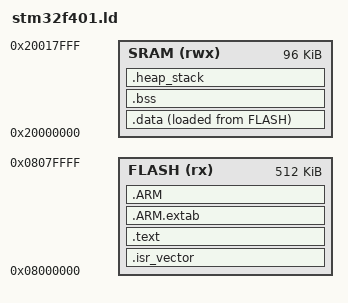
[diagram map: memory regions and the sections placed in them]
/*
 * Linker script for STM32F401RE.
 * Flash: 512 KB at 0x08000000
 * SRAM:  96 KB at 0x20000000
 *
 * Reference: STM32F401xB/C/D/E data sheet DS9716 Rev 7.
 */

MEMORY
{
    FLASH  (rx)  : ORIGIN = 0x08000000, LENGTH = 512K
    SRAM   (rwx) : ORIGIN = 0x20000000, LENGTH = 96K
}

ENTRY(Reset_Handler)

SECTIONS
{
    .isr_vector :
    {
        . = ALIGN(4);
        KEEP(*(.isr_vector))
        . = ALIGN(4);
    } > FLASH

    .text :
    {
        . = ALIGN(4);
        *(.text)
        *(.text*)
        *(.rodata)
        *(.rodata*)
        KEEP(*(.init))
        KEEP(*(.fini))
        . = ALIGN(4);
        _etext = .;
    } > FLASH

    .ARM.extab :
    {
        *(.ARM.extab* .gnu.linkonce.armextab.*)
    } > FLASH

    .ARM :
    {
        __exidx_start = .;
        *(.ARM.exidx*)
        __exidx_end = .;
    } > FLASH

    _sidata = LOADADDR(.data);

    .data :
    {
        . = ALIGN(4);
        _sdata = .;
        *(.data)
        *(.data*)
        . = ALIGN(4);
        _edata = .;
    } > SRAM AT > FLASH

    .bss :
    {
        . = ALIGN(4);
        _sbss = .;
        *(.bss)
        *(.bss*)
        *(COMMON)
        . = ALIGN(4);
        _ebss = .;
    } > SRAM

    .heap_stack :
    {
        . = ALIGN(8);
        PROVIDE(end = .);
        . = . + 0x800;    /* 2 KB heap */
        . = . + 0x1000;   /* 4 KB stack */
        . = ALIGN(8);
    } > SRAM
}

_estack = ORIGIN(SRAM) + LENGTH(SRAM);
